# Z20K14xM register map
Vendor: Zhixin Semiconductor; Series: Z20K14xM; File version: 0.1.0
CPU: CM4 r0p1, little endian, no MPU, FPU, 4 interrupt priority bits
Registers are 32-bit, read-write, reset 0x0 unless marked. A register's access mark holds for its fields unless they carry their own. Offsets are from the block's base; [hi:lo] are bit positions; {n}, {i} and the like mark numbered series.

## DMA
Base 0x40008000
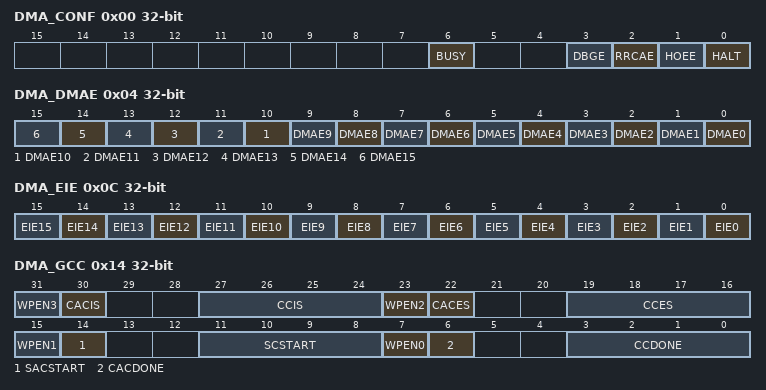
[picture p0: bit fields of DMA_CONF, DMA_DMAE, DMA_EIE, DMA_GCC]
0x00 DMA_CONF — DMA configure register(DMA_CONF)
  [6] BUSY — DMA busy status
  [3] DBGE — Debug enable
  [2] RRCAE — Round robin channel arbitration enable
  [1] HOEE — Halt on error enable
  [0] HALT — DMA operation halt
0x04 DMA_DMAE — DMA request enable register(DMA_DMAE)
  [n] DMAE{n} (n=0..15) — Channel {n} DMA request enable
0x0C DMA_EIE — DMA errror interrupt enable register(DMA_EIE)
  [n] EIE{n} (n=0..15) — Channel {n} error interrupt enable
0x14 DMA_GCC wo — DMA global channel control register(DMA_GCC)
  [8n+7] WPEN{n} (n=0..3) — Write protection for this register byte {n} bits
  [30] CACIS — Clear all channels interrupt status in CIS register
  [27:24] CCIS — Clear channel interrupt status in CIS register
  [22] CACES — Clear all channels error status in CES register
  [19:16] CCES — Clear channel error status in CES register
  [14] SACSTART — Set all channels START bit of DMA_CSx[START]
  [11:8] SCSTART — Set channel START bit of DMA_CSx[START]
  [6] CACDONE — Clear all channels DONE bit of DMA_CSx[DONE]
  [3:0] CCDONE — Clear channel DONE bit of DMA_CSx[DONE]
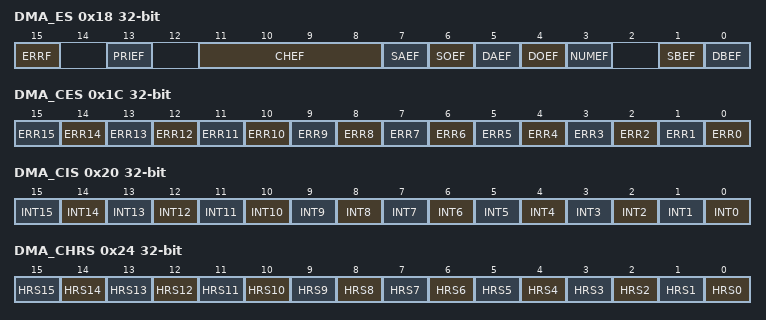
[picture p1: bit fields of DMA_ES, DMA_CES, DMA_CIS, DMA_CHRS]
0x18 DMA_ES ro — DMA error status register (DMA_ES)
  [15] ERRF — Error flag
  [13] PRIEF — Priority error flag
  [11:8] CHEF — Channel error flag
  [7] SAEF — Source address error flag
  [6] SOEF — Source address offset error flag
  [5] DAEF — destination address error flag
  [4] DOEF — destination address offset error flag
  [3] NUMEF — Number of transfer data error flag
  [1] SBEF — Source bus error flag
  [0] DBEF — Destination bus error flag
0x1C DMA_CES ro — DMA channel error status register(DMA_CES)
  [n] ERR{n} (n=0..15) — Channel {n} error flag
0x20 DMA_CIS ro — DMA channel interrupt status register(DMA_CIS)
  [n] INT{n} (n=0..15) — Channel {n} interrupt flag
0x24 DMA_CHRS ro — DMA channel hardware request status register(DMA_CHRS)
  [n] HRS{n} (n=0..15) — Channel {n} hardware request flag
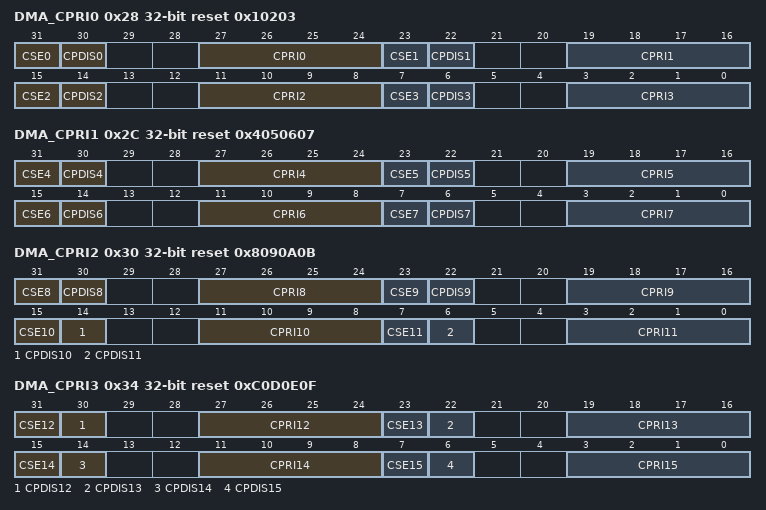
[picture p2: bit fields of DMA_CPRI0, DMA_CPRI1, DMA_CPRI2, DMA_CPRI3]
0x28 DMA_CPRI0 reset 0x10203 — DMA channel priority register 0(DMA_CPRI0)
  [31-8n] CSE{n} (n=0..3) — Channel {n} suspend enable
  [30-8n] CPDIS{n} (n=0..3) — Channel {n} preempt disable
  [27-8n:24-8n] CPRI{n} (n=0..3) — Channel {n} priority
0x2C DMA_CPRI1 reset 0x4050607 — DMA channel priority register 1(DMA_CPRI1)
  [63-8n] CSE{n} (n=4..7) — Channel {n} suspend enable
  [62-8n] CPDIS{n} (n=4..7) — Channel {n} preempt disable
  [59-8n:56-8n] CPRI{n} (n=4..7) — Channel {n} priority
0x30 DMA_CPRI2 reset 0x8090A0B — DMA channel priority register 2(DMA_CPRI2)
  [95-8n] CSE{n} (n=8..11) — Channel {n} suspend enable
  [94-8n] CPDIS{n} (n=8..11) — Channel {n} preempt disable
  [91-8n:88-8n] CPRI{n} (n=8..11) — Channel {n} priority
0x34 DMA_CPRI3 reset 0xC0D0E0F — DMA channel priority register 3(DMA_CPRI3)
  [127-8n] CSE{n} (n=12..15) — Channel {n} suspend enable
  [126-8n] CPDIS{n} (n=12..15) — Channel {n} preempt disable
  [123-8n:120-8n] CPRI{n} (n=12..15) — Channel {n} priority
{0x200+0x20*i} DMA_SADDRn{i} (i=0..15) — DMA channel n source address register(DMA_SADDRn)
  [31:0] SADDR — Channel n source address
{0x204+0x20*i} DMA_DADDRn{i} (i=0..15) — DMA channel n destination address register(DMA_DADDRn)
  [31:0] DADDR — Channel n destination address
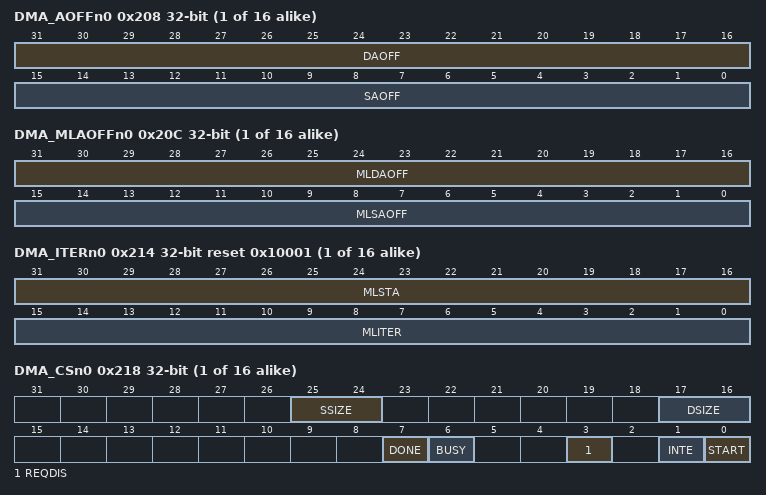
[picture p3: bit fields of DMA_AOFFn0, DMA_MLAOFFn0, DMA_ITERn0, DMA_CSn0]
{0x208+0x20*i} DMA_AOFFn{i} (i=0..15) — DMA channel n address offset register(DMA_AOFFn)
  [31:16] DAOFF — Channel n destination address offset
  [15:0] SAOFF — Channel n source address offset
{0x20C+0x20*i} DMA_MLAOFFn{i} (i=0..15) — DMA channel n Major loop address offset register(DMA_MLAOFFn)
  [31:16] MLDAOFF — Channel n major loop destination address offset
  [15:0] MLSAOFF — Channel n major loop source address offset
{0x210+0x20*i} DMA_NUMn{i} (i=0..15) — DMA channel n number of transfer data(DMA_NUMn)
  [31:0] NUM — Channel n number of transfer data in a minor loop
{0x214+0x20*i} DMA_ITERn{i} reset 0x10001 (i=0..15) — DMA channel n Iteration number register(DMA_ITERn)
  [31:16] MLSTA — Channel n minor loop status
  [15:0] MLITER — Channel n minor loop iteration number
{0x218+0x20*i} DMA_CSn{i} (i=0..15) — DMA channel n control and status register(DMA_CSn)
  [25:24] SSIZE — Channel n source data transfer size
  [17:16] DSIZE — Channel n destination data transfer size
  [7] DONE — Channel n DMA transfer done flag
  [6] BUSY — Channel n busy status
  [3] REQDIS — Channel n DMA hardware request disable
  [1] INTE — Channel n DMA major loop done interrupt enable
  [0] START — Channel n software start
